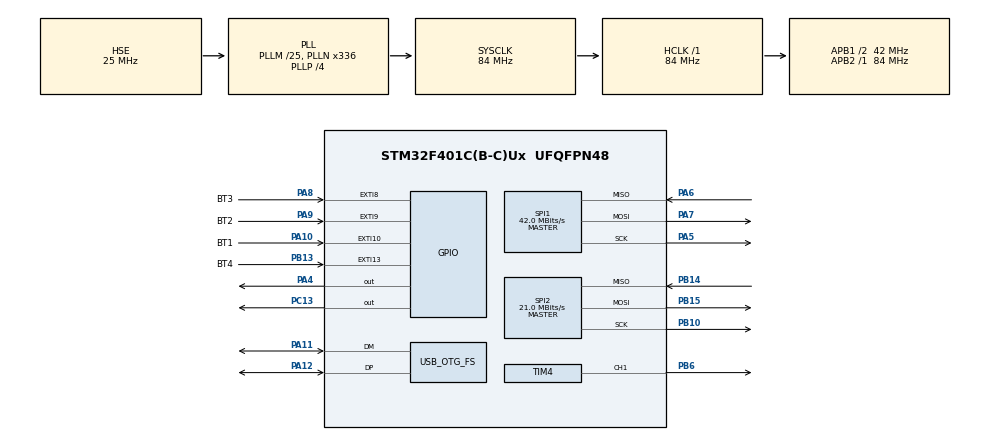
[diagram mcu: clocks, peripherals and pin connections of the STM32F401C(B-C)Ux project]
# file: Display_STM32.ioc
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Dma.Request0=TIM4_CH1
Dma.TIM4_CH1.0.Direction=DMA_MEMORY_TO_PERIPH
Dma.TIM4_CH1.0.FIFOMode=DMA_FIFOMODE_DISABLE
Dma.TIM4_CH1.0.Instance=DMA1_Stream0
Dma.TIM4_CH1.0.MemDataAlignment=DMA_MDATAALIGN_HALFWORD
Dma.TIM4_CH1.0.MemInc=DMA_MINC_ENABLE
Dma.TIM4_CH1.0.Mode=DMA_NORMAL
Dma.TIM4_CH1.0.PeriphDataAlignment=DMA_PDATAALIGN_HALFWORD
Dma.TIM4_CH1.0.PeriphInc=DMA_PINC_DISABLE
Dma.TIM4_CH1.0.Priority=DMA_PRIORITY_LOW
Mcu.Family=STM32F4
Mcu.Name=STM32F401C(B-C)Ux
Mcu.Package=UFQFPN48
Mcu.UserConstants=LED_CNT,125
NVIC.DMA1_Stream0_IRQn=true\:0\:0\:false\:false\:true\:false\:true\:true
NVIC.EXTI15_10_IRQn=true\:0\:0\:false\:false\:true\:true\:true\:true
NVIC.EXTI9_5_IRQn=true\:0\:0\:false\:false\:true\:true\:true\:true
NVIC.PriorityGroup=NVIC_PRIORITYGROUP_4
PA10.GPIO_Label=BT1
PA10.GPIO_ModeDefaultEXTI=GPIO_MODE_IT_FALLING
PA10.Signal=GPXTI10
PA11.Mode=Device_Only
PA11.Signal=USB_OTG_FS_DM
PA12.Mode=Device_Only
PA12.Signal=USB_OTG_FS_DP
PA4.Signal=GPIO_Output
PA5.Mode=Full_Duplex_Master
PA5.Signal=SPI1_SCK
PA6.Mode=Full_Duplex_Master
PA6.Signal=SPI1_MISO
PA7.Mode=Full_Duplex_Master
PA7.Signal=SPI1_MOSI
PA8.GPIO_Label=BT3
PA8.GPIO_ModeDefaultEXTI=GPIO_MODE_IT_FALLING
PA8.Signal=GPXTI8
PA9.GPIO_Label=BT2
PA9.GPIO_ModeDefaultEXTI=GPIO_MODE_IT_FALLING
PA9.Signal=GPXTI9
PB10.Mode=Full_Duplex_Master
PB10.Signal=SPI2_SCK
PB13.GPIO_Label=BT4
PB13.GPIO_ModeDefaultEXTI=GPIO_MODE_IT_RISING_FALLING
PB13.Signal=GPXTI13
PB14.Mode=Full_Duplex_Master
PB14.Signal=SPI2_MISO
PB15.Mode=Full_Duplex_Master
PB15.Signal=SPI2_MOSI
PB6.Signal=S_TIM4_CH1
PC13-ANTI_TAMP.Signal=GPIO_Output
PC14-OSC32_IN.Mode=LSE-External-Oscillator
PC14-OSC32_IN.Signal=RCC_OSC32_IN
PC15-OSC32_OUT.Mode=LSE-External-Oscillator
PC15-OSC32_OUT.Signal=RCC_OSC32_OUT
PH0\ -\ OSC_IN.Mode=HSE-External-Oscillator
PH0\ -\ OSC_IN.Signal=RCC_OSC_IN
PH1\ -\ OSC_OUT.Mode=HSE-External-Oscillator
PH1\ -\ OSC_OUT.Signal=RCC_OSC_OUT
ProjectManager.HeapSize=0x200
ProjectManager.StackSize=0x400
ProjectManager.TargetToolchain=STM32CubeIDE
RCC.48MHZClocksFreq_Value=48000000
RCC.AHBFreq_Value=84000000
RCC.APB1CLKDivider=RCC_HCLK_DIV2
RCC.APB1Freq_Value=42000000
RCC.APB1TimFreq_Value=84000000
RCC.APB2Freq_Value=84000000
RCC.APB2TimFreq_Value=84000000
RCC.CortexFreq_Value=84000000
RCC.HCLKFreq_Value=84000000
RCC.HSE_VALUE=25000000
RCC.HSI_VALUE=16000000
RCC.PLLM=25
RCC.PLLN=336
RCC.PLLP=RCC_PLLP_DIV4
RCC.PLLQ=7
RCC.SYSCLKFreq_VALUE=84000000
RCC.SYSCLKSource=RCC_SYSCLKSOURCE_PLLCLK
RCC.VCOOutputFreq_Value=336000000
SH.S_TIM4_CH1.0=TIM4_CH1,PWM Generation1 CH1
SPI1.BaudRatePrescaler=SPI_BAUDRATEPRESCALER_2
SPI1.CalculateBaudRate=42.0 MBits/s
SPI1.Direction=SPI_DIRECTION_2LINES
SPI1.Mode=SPI_MODE_MASTER
SPI1.VirtualType=VM_MASTER
SPI2.CalculateBaudRate=21.0 MBits/s
SPI2.Direction=SPI_DIRECTION_2LINES
SPI2.Mode=SPI_MODE_MASTER
SPI2.VirtualType=VM_MASTER
TIM4.Channel-PWM\ Generation1\ CH1=TIM_CHANNEL_1
TIM4.Period=105
USB_OTG_FS.VirtualMode=Device_Only
VP_TIM4_VS_ClockSourceINT.Mode=Internal
board=custom

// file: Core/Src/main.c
/* USER CODE BEGIN Header */
/**
  ******************************************************************************
  * @file           : main.c
  * @brief          : Main program body
  ******************************************************************************
  * @attention
  *
  * Copyright (c) 2025 STMicroelectronics.
  * All rights reserved.
  *
  * This software is licensed under terms that can be found in the LICENSE file
  * in the root directory of this software component.
  * If no LICENSE file comes with this software, it is provided AS-IS.
  *
  ******************************************************************************
  */
/* USER CODE END Header */
#include "main.h"
#include "dma.h"
#include "spi.h"
#include "tim.h"
#include "usb_otg.h"
#include "gpio.h"

/* USER CODE BEGIN Includes */
#include "mcp2515user.h"
/* USER CODE END Includes */

void SystemClock_Config(void);

/* USER CODE BEGIN 0 */
//struct can_frame frame;
//uint16_t RPM;

//void getCAN() {
//    if (readMessage(&frame) == 0) {
        // Check for correct CAN ID
//        if (frame.can_id == 0x5E8) { // 1512 decimal
//            // Extract 2 bytes starting at offset 2
//            RPM = (frame.data[2] << 8) | frame.data[3];
//        }
//    } else {
//   	HAL_GPIO_WritePin(GPIOC, GPIO_PIN_13, GPIO_PIN_SET);   // LED ON
//  }
//}
/* USER CODE END 0 */

int main(void)
{

  /* MCU Configuration--------------------------------------------------------*/

  /* Reset of all peripherals, Initializes the Flash interface and the Systick. */
  HAL_Init();

  /* Configure the system clock */
  SystemClock_Config();

  /* Initialize all configured peripherals */
  MX_GPIO_Init();
  MX_DMA_Init();
  MX_SPI1_Init();
  MX_TIM4_Init();
  MX_USB_OTG_FS_PCD_Init();
  MX_SPI2_Init();
  /* USER CODE BEGIN 2 */
  initializeMCP2515();

  // Storage arrays for each color, and byte count
  uint8_t ledcolors[3 * 16];
  uint16_t ledbytes[(16 * 24) + 150];
  int G1[12] = {834, 1668, 2502, 3336, 4170, 5004, 5838, 6672, 7506, 8340,
  9174, 10008};
  struct can_frame frame;
  uint16_t RPM;

  shiftLightsInit(&htim4, TIM_CHANNEL_1, ledcolors, ledbytes);
  HAL_Delay(1000);
  startUp(&htim4, TIM_CHANNEL_1, ledcolors, ledbytes);
  for (int i = 0; i < 11000; i += 834) {
  	UpdateShiftLights(&htim4, TIM_CHANNEL_1, ledcolors, ledbytes, i, G1);
  }
  //setColor(&htim4, TIM_CHANNEL_1, 0, 255, 0, ledcolors, ledbytes, 2);
  /* USER CODE END 2 */

  /* Infinite loop */
  while (1)
  {

    /* USER CODE BEGIN 3 */

	/*
	if (readMessage(&frame)) {
		if (frame.can_id == 1520) { // 1520 decimal
			//Extract 2 bytes starting at offset 2
			RPM = ((uint16_t)frame.data[2] << 8) | frame.data[3];
		}
		UpdateShiftLights(&htim4, TIM_CHANNEL_1, ledcolors, ledbytes, RPM, G1);
	}
	*/
	  UpdateShiftLights(&htim4, TIM_CHANNEL_1, ledcolors, ledbytes, 10500, G1);

	  //HAL_GPIO_WritePin(GPIOC, GPIO_PIN_13, GPIO_PIN_SET);   // LED ON
	  //HAL_Delay(500);  // 500ms delay

	  //HAL_GPIO_WritePin(GPIOC, GPIO_PIN_13, GPIO_PIN_RESET); // LED OFF
	  //HAL_Delay(500);  // 500ms delay
  }
  /* USER CODE END 3 */
}

void SystemClock_Config(void)
{
  RCC_OscInitTypeDef RCC_OscInitStruct = {0};
  RCC_ClkInitTypeDef RCC_ClkInitStruct = {0};

  /** Configure the main internal regulator output voltage
  */
  __HAL_RCC_PWR_CLK_ENABLE();
  __HAL_PWR_VOLTAGESCALING_CONFIG(PWR_REGULATOR_VOLTAGE_SCALE2);

  /** Initializes the RCC Oscillators according to the specified parameters
  * in the RCC_OscInitTypeDef structure.
  */
  RCC_OscInitStruct.OscillatorType = RCC_OSCILLATORTYPE_HSE;
  RCC_OscInitStruct.HSEState = RCC_HSE_ON;
  RCC_OscInitStruct.PLL.PLLState = RCC_PLL_ON;
  RCC_OscInitStruct.PLL.PLLSource = RCC_PLLSOURCE_HSE;
  RCC_OscInitStruct.PLL.PLLM = 25;
  RCC_OscInitStruct.PLL.PLLN = 336;
  RCC_OscInitStruct.PLL.PLLP = RCC_PLLP_DIV4;
  RCC_OscInitStruct.PLL.PLLQ = 7;
  if (HAL_RCC_OscConfig(&RCC_OscInitStruct) != HAL_OK)
  {
    Error_Handler();
  }

  /** Initializes the CPU, AHB and APB buses clocks
  */
  RCC_ClkInitStruct.ClockType = RCC_CLOCKTYPE_HCLK|RCC_CLOCKTYPE_SYSCLK
                              |RCC_CLOCKTYPE_PCLK1|RCC_CLOCKTYPE_PCLK2;
  RCC_ClkInitStruct.SYSCLKSource = RCC_SYSCLKSOURCE_PLLCLK;
  RCC_ClkInitStruct.AHBCLKDivider = RCC_SYSCLK_DIV1;
  RCC_ClkInitStruct.APB1CLKDivider = RCC_HCLK_DIV2;
  RCC_ClkInitStruct.APB2CLKDivider = RCC_HCLK_DIV1;

  if (HAL_RCC_ClockConfig(&RCC_ClkInitStruct, FLASH_LATENCY_2) != HAL_OK)
  {
    Error_Handler();
  }
}

void Error_Handler(void)
{
  __disable_irq();
  while (1)
  {
  }
}
